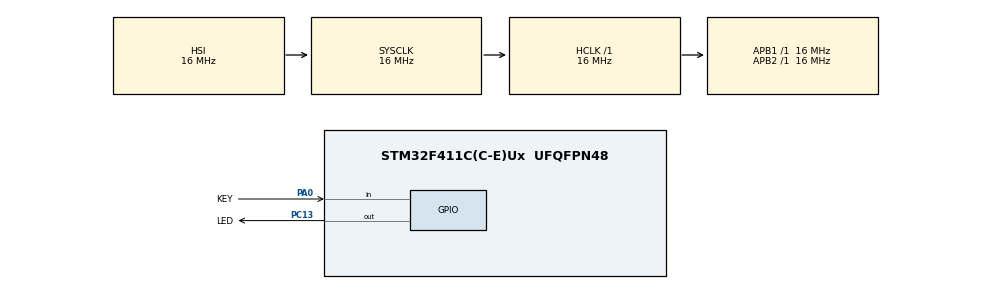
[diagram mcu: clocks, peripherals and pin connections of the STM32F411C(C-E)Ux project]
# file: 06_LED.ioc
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Mcu.Family=STM32F4
Mcu.Name=STM32F411C(C-E)Ux
Mcu.Package=UFQFPN48
NVIC.PriorityGroup=NVIC_PRIORITYGROUP_4
PA0-WKUP.GPIO_Label=KEY
PA0-WKUP.GPIO_PuPd=GPIO_PULLUP
PA0-WKUP.Signal=GPIO_Input
PA13.Mode=Serial_Wire
PA13.Signal=SYS_JTMS-SWDIO
PA14.Mode=Serial_Wire
PA14.Signal=SYS_JTCK-SWCLK
PC13-ANTI_TAMP.GPIO_Label=LED
PC13-ANTI_TAMP.Signal=GPIO_Output
PC14-OSC32_IN.Mode=LSE-External-Oscillator
PC14-OSC32_IN.Signal=RCC_OSC32_IN
PC15-OSC32_OUT.Mode=LSE-External-Oscillator
PC15-OSC32_OUT.Signal=RCC_OSC32_OUT
PH0\ -\ OSC_IN.Mode=HSE-External-Oscillator
PH0\ -\ OSC_IN.Signal=RCC_OSC_IN
PH1\ -\ OSC_OUT.Mode=HSE-External-Oscillator
PH1\ -\ OSC_OUT.Signal=RCC_OSC_OUT
ProjectManager.HeapSize=0x200
ProjectManager.StackSize=0x400
ProjectManager.TargetToolchain=MDK-ARM V5
RCC.AHBFreq_Value=16000000
RCC.APB1Freq_Value=16000000
RCC.APB2Freq_Value=16000000
RCC.CortexFreq_Value=16000000
RCC.HSE_VALUE=25000000
RCC.HSI_VALUE=16000000
RCC.SYSCLKFreq_VALUE=16000000
RCC.VCOOutputFreq_Value=192000000
board=custom

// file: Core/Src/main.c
/* USER CODE BEGIN Header */
/**
  ******************************************************************************
  * @file           : main.c
  * @brief          : Main program body
  ******************************************************************************
  * @attention
  *
  * Copyright (c) 2026 STMicroelectronics.
  * All rights reserved.
  *
  * This software is licensed under terms that can be found in the LICENSE file
  * in the root directory of this software component.
  * If no LICENSE file comes with this software, it is provided AS-IS.
  *
  ******************************************************************************
  */
/* USER CODE END Header */
#include "main.h"
#include "gpio.h"

void SystemClock_Config(void);

int main(void)
{

  /* MCU Configuration--------------------------------------------------------*/

  /* Reset of all peripherals, Initializes the Flash interface and the Systick. */
  HAL_Init();

  /* Configure the system clock */
  SystemClock_Config();

  /* Initialize all configured peripherals */
  MX_GPIO_Init();

  /* Infinite loop */
  /* USER CODE BEGIN WHILE */
  while (1)
  {
		//key pin上拉，key_pin==1; 按下按键key_pin==0
		if(HAL_GPIO_ReadPin(KEY_GPIO_Port, KEY_Pin)==0)
		{
			//led_pin输出高电平，根据电路两边为高电平，没有压差，led熄灭
			HAL_GPIO_WritePin(LED_GPIO_Port, LED_Pin, GPIO_PIN_SET);
		}
		//反之则亮
		else
		{
			HAL_GPIO_WritePin(LED_GPIO_Port, LED_Pin, GPIO_PIN_RESET);
		}

//			HAL_GPIO_WritePin(LED_GPIO_Port, LED_Pin, GPIO_PIN_RESET);
//			HAL_Delay(1000);
//			HAL_GPIO_WritePin(LED_GPIO_Port, LED_Pin, GPIO_PIN_SET);
//			HAL_Delay(1000);
//

    /* USER CODE END WHILE */

  }
}

void SystemClock_Config(void)
{
  RCC_OscInitTypeDef RCC_OscInitStruct = {0};
  RCC_ClkInitTypeDef RCC_ClkInitStruct = {0};

  /** Configure the main internal regulator output voltage
  */
  __HAL_RCC_PWR_CLK_ENABLE();
  __HAL_PWR_VOLTAGESCALING_CONFIG(PWR_REGULATOR_VOLTAGE_SCALE1);

  /** Initializes the RCC Oscillators according to the specified parameters
  * in the RCC_OscInitTypeDef structure.
  */
  RCC_OscInitStruct.OscillatorType = RCC_OSCILLATORTYPE_HSI;
  RCC_OscInitStruct.HSIState = RCC_HSI_ON;
  RCC_OscInitStruct.HSICalibrationValue = RCC_HSICALIBRATION_DEFAULT;
  RCC_OscInitStruct.PLL.PLLState = RCC_PLL_NONE;
  if (HAL_RCC_OscConfig(&RCC_OscInitStruct) != HAL_OK)
  {
    Error_Handler();
  }

  /** Initializes the CPU, AHB and APB buses clocks
  */
  RCC_ClkInitStruct.ClockType = RCC_CLOCKTYPE_HCLK|RCC_CLOCKTYPE_SYSCLK
                              |RCC_CLOCKTYPE_PCLK1|RCC_CLOCKTYPE_PCLK2;
  RCC_ClkInitStruct.SYSCLKSource = RCC_SYSCLKSOURCE_HSI;
  RCC_ClkInitStruct.AHBCLKDivider = RCC_SYSCLK_DIV1;
  RCC_ClkInitStruct.APB1CLKDivider = RCC_HCLK_DIV1;
  RCC_ClkInitStruct.APB2CLKDivider = RCC_HCLK_DIV1;

  if (HAL_RCC_ClockConfig(&RCC_ClkInitStruct, FLASH_LATENCY_0) != HAL_OK)
  {
    Error_Handler();
  }
}

void Error_Handler(void)
{
  __disable_irq();
  while (1)
  {
  }
}
